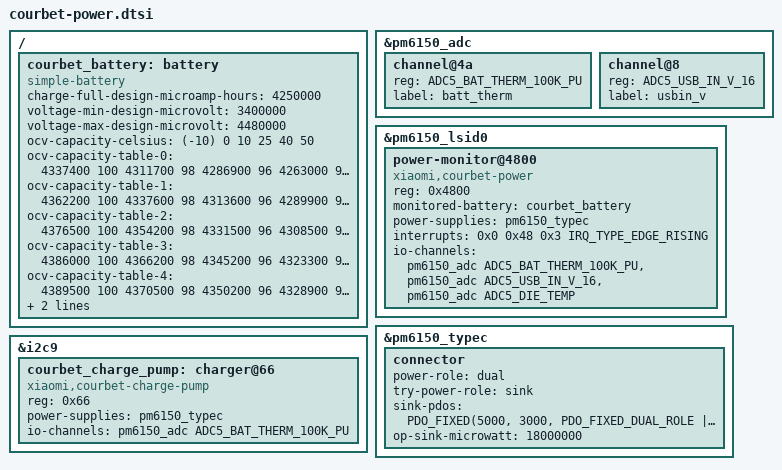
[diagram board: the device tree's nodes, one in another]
// SPDX-License-Identifier: GPL-2.0-only
/ {
	courbet_battery: battery {
		compatible = "simple-battery";
		/* OEM K9A 4250 mAh cosmx profile; OCV anchor for the native coulomb counter. */
		charge-full-design-microamp-hours = <4250000>;
		voltage-min-design-microvolt = <3400000>;
		voltage-max-design-microvolt = <4480000>;
		ocv-capacity-celsius = <(-10) 0 10 25 40 50>;
		ocv-capacity-table-0 = <4337400 100
			4311700 98
			4286900 96
			4263000 94
			4239800 92
			4217100 90
			4194900 88
			4173200 86
			4151800 84
			4130700 82
			4109900 80
			4089700 78
			4070000 76
			4050700 74
			4031400 72
			4012300 70
			3995200 68
			3980500 66
			3967400 64
			3955500 62
			3944800 60
			3934400 58
			3922700 56
			3909200 54
			3895900 52
			3884700 50
			3874400 48
			3865200 46
			3857500 44
			3850600 42
			3844800 40
			3839900 38
			3835700 36
			3831800 34
			3828300 32
			3824900 30
			3821300 28
			3817600 26
			3813600 24
			3807900 22
			3797500 20
			3784800 18
			3770400 16
			3755800 14
			3742300 12
			3730600 10
			3726100 9
			3722300 8
			3718600 7
			3713200 6
			3697300 5
			3662400 4
			3609900 3
			3542200 2
			3427400 1
			3000000 0>;
		ocv-capacity-table-1 = <4362200 100
			4337600 98
			4313600 96
			4289900 94
			4266500 92
			4242800 90
			4219200 88
			4196300 86
			4173900 84
			4152100 82
			4130800 80
			4110000 78
			4089700 76
			4069900 74
			4050500 72
			4031900 70
			4013800 68
			3996600 66
			3981000 64
			3966800 62
			3952900 60
			3938200 58
			3923200 56
			3908000 54
			3891700 52
			3875900 50
			3864100 48
			3855000 46
			3847800 44
			3841800 42
			3836800 40
			3832400 38
			3828700 36
			3825300 34
			3822200 32
			3819500 30
			3816600 28
			3812400 26
			3806000 24
			3797900 22
			3787600 20
			3774300 18
			3758800 16
			3743100 14
			3733700 12
			3723700 10
			3719800 9
			3716600 8
			3713200 7
			3705500 6
			3682200 5
			3636200 4
			3577400 3
			3498300 2
			3368600 1
			3000000 0>;
		ocv-capacity-table-2 = <4376500 100
			4354200 98
			4331500 96
			4308500 94
			4285000 92
			4261400 90
			4237800 88
			4214200 86
			4191100 84
			4168400 82
			4146300 80
			4124800 78
			4104100 76
			4083800 74
			4063400 72
			4043500 70
			4025200 68
			4008800 66
			3992700 64
			3975900 62
			3958900 60
			3940400 58
			3917300 56
			3894000 54
			3878900 52
			3869000 50
			3861000 48
			3853700 46
			3847100 44
			3841100 42
			3835600 40
			3830600 38
			3826200 36
			3822200 34
			3818600 32
			3815300 30
			3812200 28
			3807900 26
			3800600 24
			3791100 22
			3780300 20
			3767300 18
			3752500 16
			3735800 14
			3722300 12
			3714600 10
			3712000 9
			3710000 8
			3707200 7
			3699200 6
			3670300 5
			3623300 4
			3562800 3
			3480000 2
			3346100 1
			3000000 0>;
		ocv-capacity-table-3 = <4386000 100
			4366200 98
			4345200 96
			4323300 94
			4300700 92
			4277100 90
			4253300 88
			4229600 86
			4206100 84
			4182800 82
			4159800 80
			4137400 78
			4115700 76
			4094800 74
			4074500 72
			4054800 70
			4035800 68
			4018100 66
			4001700 64
			3983700 62
			3960300 60
			3935000 58
			3915500 56
			3900200 54
			3887200 52
			3875800 50
			3866000 48
			3856800 46
			3848100 44
			3840200 42
			3833200 40
			3826800 38
			3821300 36
			3816600 34
			3812400 32
			3808100 30
			3804100 28
			3799200 26
			3792000 24
			3782400 22
			3771900 20
			3759900 18
			3746000 16
			3729300 14
			3715900 12
			3708100 10
			3706000 9
			3704200 8
			3702300 7
			3694300 6
			3663500 5
			3617000 4
			3557600 3
			3476400 2
			3348600 1
			3000000 0>;
		ocv-capacity-table-4 = <4389500 100
			4370500 98
			4350200 96
			4328900 94
			4306700 92
			4283400 90
			4259700 88
			4236100 86
			4212700 84
			4189400 82
			4166300 80
			4143500 78
			4121300 76
			4099800 74
			4078800 72
			4058700 70
			4039400 68
			4021100 66
			4004700 64
			3987700 62
			3966000 60
			3940300 58
			3918900 56
			3903000 54
			3889300 52
			3877000 50
			3865800 48
			3855700 46
			3846500 44
			3838000 42
			3830400 40
			3823500 38
			3817200 36
			3811600 34
			3806500 32
			3801200 30
			3795700 28
			3789600 26
			3781700 24
			3772000 22
			3761400 20
			3749600 18
			3736200 16
			3719500 14
			3708100 12
			3701000 10
			3699000 9
			3697500 8
			3695000 7
			3686000 6
			3653000 5
			3607200 4
			3548200 3
			3467600 2
			3341900 1
			3000000 0>;
		ocv-capacity-table-5 = <4390300 100
			4371200 98
			4351100 96
			4330200 94
			4308500 92
			4285700 90
			4262200 88
			4238600 86
			4214900 84
			4191400 82
			4168400 80
			4145900 78
			4123700 76
			4102100 74
			4080900 72
			4060600 70
			4041100 68
			4022400 66
			4005500 64
			3988500 62
			3967800 60
			3942700 58
			3920500 56
			3904100 54
			3890200 52
			3877600 50
			3866400 48
			3856100 46
			3846500 44
			3837600 42
			3829800 40
			3822700 38
			3816100 36
			3809800 34
			3804000 32
			3797700 30
			3791100 28
			3783800 26
			3775300 24
			3765500 22
			3754800 20
			3742600 18
			3729100 16
			3712900 14
			3701100 12
			3695200 10
			3693300 9
			3691500 8
			3689100 7
			3679200 6
			3644900 5
			3599100 4
			3539500 3
			3457800 2
			3329500 1
			3000000 0>;
	};
};

&pm6150_adc {
	channel@4a {
		reg = <ADC5_BAT_THERM_100K_PU>;
		label = "batt_therm";
	};
	channel@8 {
		reg = <ADC5_USB_IN_V_16>;
		label = "usbin_v";
	};
};

&pm6150_lsid0 {
	power-monitor@4800 {
		compatible = "xiaomi,courbet-power";
		reg = <0x4800>;
		monitored-battery = <&courbet_battery>;
		power-supplies = <&pm6150_typec>;
		interrupts = <0x0 0x48 0x3 IRQ_TYPE_EDGE_RISING>;
		interrupt-names = "qg-fifo-done";
		io-channels = <&pm6150_adc ADC5_BAT_THERM_100K_PU>,
			      <&pm6150_adc ADC5_USB_IN_V_16>,
			      <&pm6150_adc ADC5_DIE_TEMP>;
		io-channel-names = "batt-therm", "usbin-v", "die-temp";
	};
};

&pm6150_typec {
	connector {
		power-role = "dual";
		try-power-role = "sink";
		/* Fixed PD up to 9 V, or supervised PPS up to 10 V. */
		sink-pdos = <PDO_FIXED(5000, 3000, PDO_FIXED_DUAL_ROLE |
			       PDO_FIXED_USB_COMM | PDO_FIXED_DATA_SWAP)
			     PDO_FIXED(9000, 2000, 0)
			     PDO_PPS_APDO(3300, 10000, 3000)>;
		op-sink-microwatt = <18000000>;
	};
};

&i2c9 {
	courbet_charge_pump: charger@66 {
		compatible = "xiaomi,courbet-charge-pump";
		reg = <0x66>;
		power-supplies = <&pm6150_typec>;
		io-channels = <&pm6150_adc ADC5_BAT_THERM_100K_PU>;
		io-channel-names = "batt-therm";
	};
};
